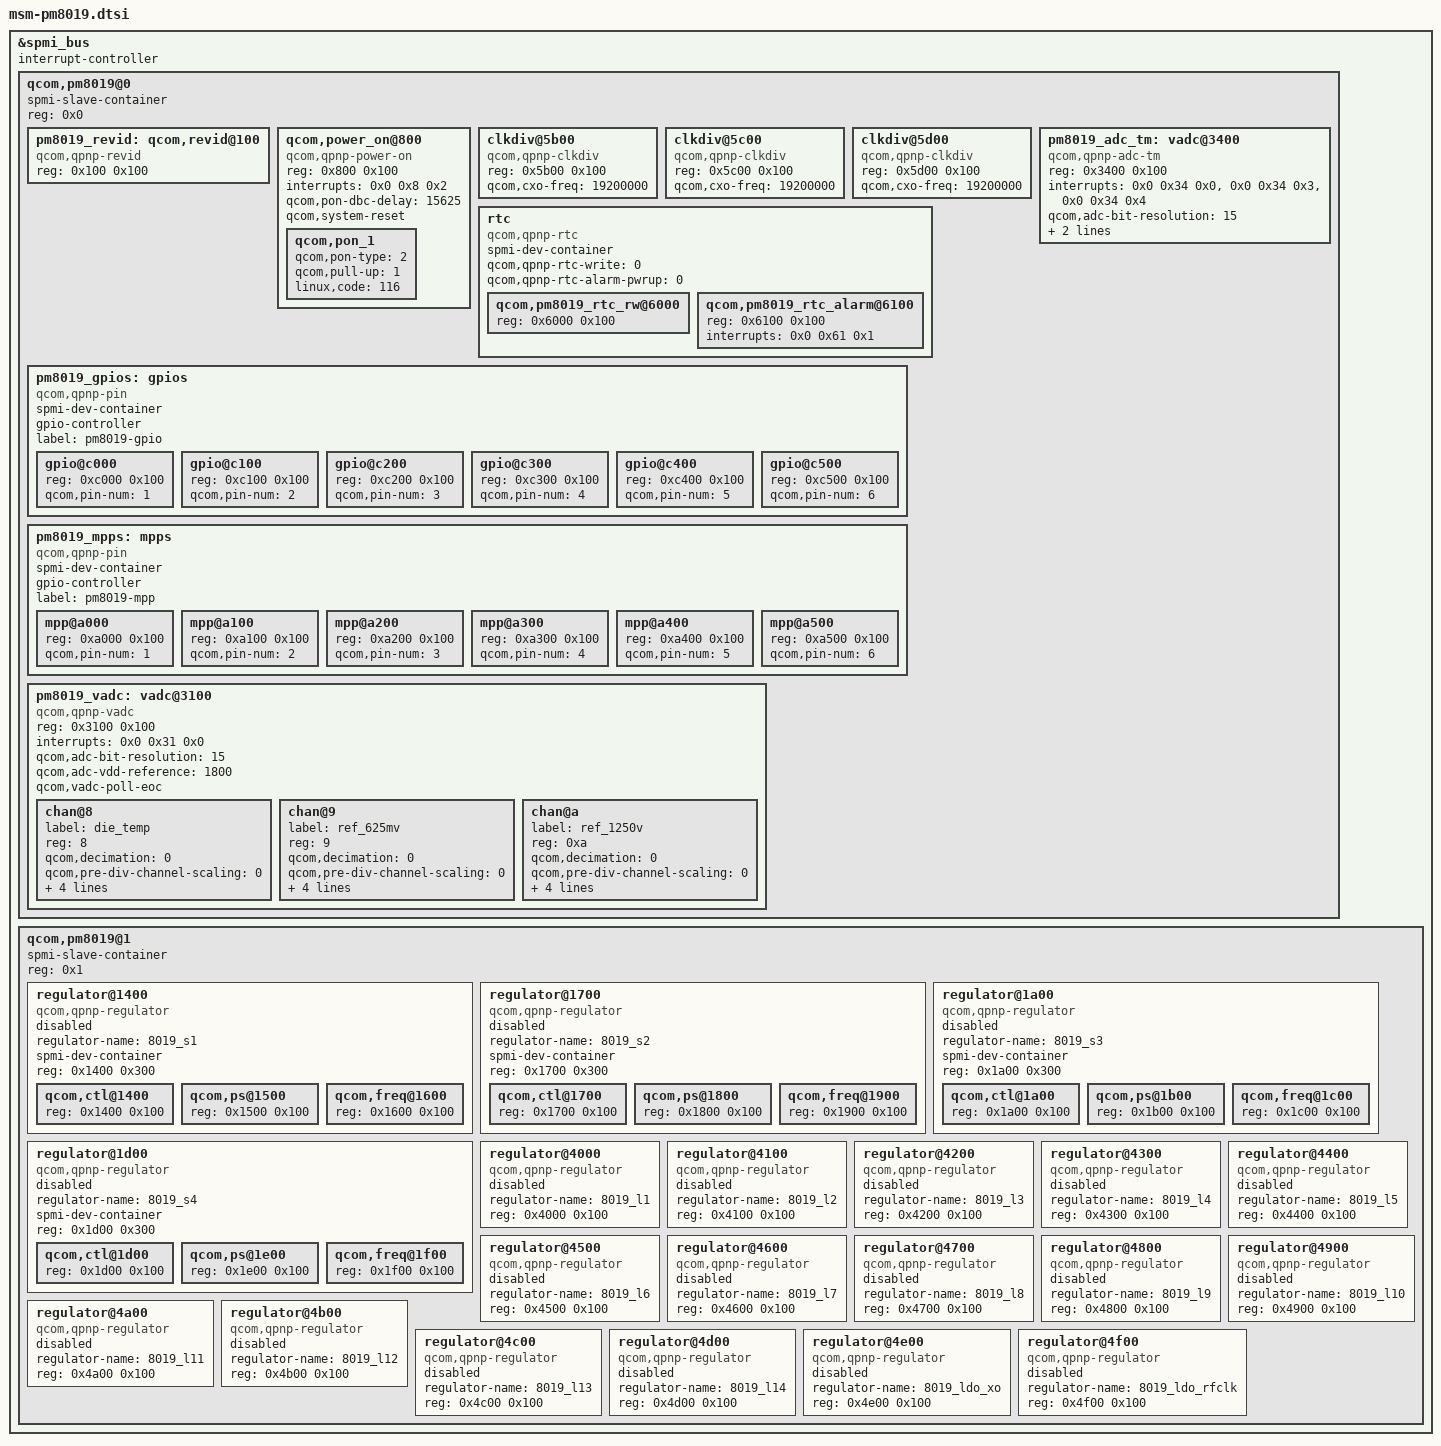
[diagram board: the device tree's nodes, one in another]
/* Copyright (c) 2012,2013,2015, Linux Foundation. All rights reserved.
 *
 * This program is free software; you can redistribute it and/or modify
 * it under the terms of the GNU General Public License version 2 and
 * only version 2 as published by the Free Software Foundation.
 *
 * This program is distributed in the hope that it will be useful,
 * but WITHOUT ANY WARRANTY; without even the implied warranty of
 * MERCHANTABILITY or FITNESS FOR A PARTICULAR PURPOSE.  See the
 * GNU General Public License for more details.
 */

&spmi_bus {
	#address-cells = <1>;
	#size-cells = <0>;
	interrupt-controller;
	#interrupt-cells = <3>;

	qcom,pm8019@0 {
		spmi-slave-container;
		reg = <0x0>;
		#address-cells = <1>;
		#size-cells = <1>;

		pm8019_revid: qcom,revid@100 {
			compatible = "qcom,qpnp-revid";
			reg = <0x100 0x100>;
		};

		qcom,power_on@800 {
			compatible = "qcom,qpnp-power-on";
			reg = <0x800 0x100>;
			interrupts = <0x0 0x8 0x2>;
			interrupt-names = "cblpwr";
			qcom,pon-dbc-delay = <15625>;
			qcom,system-reset;

			qcom,pon_1 {
				qcom,pon-type = <2>;
				qcom,pull-up = <1>;
				linux,code = <116>;
			};
		};

		clkdiv@5b00 {
			reg = <0x5b00 0x100>;
			compatible = "qcom,qpnp-clkdiv";
			qcom,cxo-freq = <19200000>;
		};

		clkdiv@5c00 {
			reg = <0x5c00 0x100>;
			compatible = "qcom,qpnp-clkdiv";
			qcom,cxo-freq = <19200000>;
		};

		clkdiv@5d00 {
			reg = <0x5d00 0x100>;
			compatible = "qcom,qpnp-clkdiv";
			qcom,cxo-freq = <19200000>;
		};

		rtc {
			spmi-dev-container;
			compatible = "qcom,qpnp-rtc";
			#address-cells = <1>;
			#size-cells = <1>;
			qcom,qpnp-rtc-write = <0>;
			qcom,qpnp-rtc-alarm-pwrup = <0>;

			qcom,pm8019_rtc_rw@6000 {
				reg = <0x6000 0x100>;
			};

			qcom,pm8019_rtc_alarm@6100 {
				reg = <0x6100 0x100>;
				interrupts = <0x0 0x61 0x1>;
			};
		};

		pm8019_gpios: gpios {
			spmi-dev-container;
			compatible = "qcom,qpnp-pin";
			gpio-controller;
			#gpio-cells = <2>;
			#address-cells = <1>;
			#size-cells = <1>;
			label = "pm8019-gpio";

			gpio@c000 {
				reg = <0xc000 0x100>;
				qcom,pin-num = <1>;
			};

			gpio@c100 {
				reg = <0xc100 0x100>;
				qcom,pin-num = <2>;
			};

			gpio@c200 {
				reg = <0xc200 0x100>;
				qcom,pin-num = <3>;
			};

			gpio@c300 {
				reg = <0xc300 0x100>;
				qcom,pin-num = <4>;
			};

			gpio@c400 {
				reg = <0xc400 0x100>;
				qcom,pin-num = <5>;
			};

			gpio@c500 {
				reg = <0xc500 0x100>;
				qcom,pin-num = <6>;
			};
		};

		pm8019_mpps: mpps {
			spmi-dev-container;
			compatible = "qcom,qpnp-pin";
			gpio-controller;
			#gpio-cells = <2>;
			#address-cells = <1>;
			#size-cells = <1>;
			label = "pm8019-mpp";

			mpp@a000 {
				reg = <0xa000 0x100>;
				qcom,pin-num = <1>;
			};

			mpp@a100 {
				reg = <0xa100 0x100>;
				qcom,pin-num = <2>;
			};

			mpp@a200 {
				reg = <0xa200 0x100>;
				qcom,pin-num = <3>;
			};

			mpp@a300 {
				reg = <0xa300 0x100>;
				qcom,pin-num = <4>;
			};

			mpp@a400 {
				reg = <0xa400 0x100>;
				qcom,pin-num = <5>;
			};

			mpp@a500 {
				reg = <0xa500 0x100>;
				qcom,pin-num = <6>;
			};
		};

		pm8019_vadc: vadc@3100 {
			compatible = "qcom,qpnp-vadc";
			reg = <0x3100 0x100>;
			#address-cells = <1>;
			#size-cells = <0>;
			interrupts = <0x0 0x31 0x0>;
			interrupt-names = "eoc-int-en-set";
			qcom,adc-bit-resolution = <15>;
			qcom,adc-vdd-reference = <1800>;
			qcom,vadc-poll-eoc;

			chan@8 {
				label = "die_temp";
				reg = <8>;
				qcom,decimation = <0>;
				qcom,pre-div-channel-scaling = <0>;
				qcom,calibration-type = "absolute";
				qcom,scale-function = <3>;
				qcom,hw-settle-time = <0>;
				qcom,fast-avg-setup = <0>;
			};

			chan@9 {
				label = "ref_625mv";
				reg = <9>;
				qcom,decimation = <0>;
				qcom,pre-div-channel-scaling = <0>;
				qcom,calibration-type = "absolute";
				qcom,scale-function = <0>;
				qcom,hw-settle-time = <0>;
				qcom,fast-avg-setup = <0>;
			};

			chan@a {
				label = "ref_1250v";
				reg = <0xa>;
				qcom,decimation = <0>;
				qcom,pre-div-channel-scaling = <0>;
				qcom,calibration-type = "absolute";
				qcom,scale-function = <0>;
				qcom,hw-settle-time = <0>;
				qcom,fast-avg-setup = <0>;
			};
		};

		pm8019_adc_tm: vadc@3400 {
			compatible = "qcom,qpnp-adc-tm";
			reg = <0x3400 0x100>;
			#address-cells = <1>;
			#size-cells = <0>;
			interrupts =	<0x0 0x34 0x0>,
					<0x0 0x34 0x3>,
				     <0x0 0x34 0x4>;
			interrupt-names =	"eoc-int-en-set",
						"high-thr-en-set",
						"low-thr-en-set";
			qcom,adc-bit-resolution = <15>;
			qcom,adc_tm-vadc = <&pm8019_vadc>;
			qcom,adc-vdd-reference = <1800>;
		};
	};

	qcom,pm8019@1 {
		spmi-slave-container;
		reg = <0x1>;
		#address-cells = <1>;
		#size-cells = <1>;

		regulator@1400 {
			regulator-name = "8019_s1";
			spmi-dev-container;
			#address-cells = <1>;
			#size-cells = <1>;
			compatible = "qcom,qpnp-regulator";
			reg = <0x1400 0x300>;
			status = "disabled";

			qcom,ctl@1400 {
				reg = <0x1400 0x100>;
			};
			qcom,ps@1500 {
				reg = <0x1500 0x100>;
			};
			qcom,freq@1600 {
				reg = <0x1600 0x100>;
			};
		};

		regulator@1700 {
			regulator-name = "8019_s2";
			spmi-dev-container;
			#address-cells = <1>;
			#size-cells = <1>;
			compatible = "qcom,qpnp-regulator";
			reg = <0x1700 0x300>;
			status = "disabled";

			qcom,ctl@1700 {
				reg = <0x1700 0x100>;
			};
			qcom,ps@1800 {
				reg = <0x1800 0x100>;
			};
			qcom,freq@1900 {
				reg = <0x1900 0x100>;
			};
		};

		regulator@1a00 {
			regulator-name = "8019_s3";
			spmi-dev-container;
			#address-cells = <1>;
			#size-cells = <1>;
			compatible = "qcom,qpnp-regulator";
			reg = <0x1a00 0x300>;
			status = "disabled";

			qcom,ctl@1a00 {
				reg = <0x1a00 0x100>;
			};
			qcom,ps@1b00 {
				reg = <0x1b00 0x100>;
			};
			qcom,freq@1c00 {
				reg = <0x1c00 0x100>;
			};
		};

		regulator@1d00 {
			regulator-name = "8019_s4";
			spmi-dev-container;
			#address-cells = <1>;
			#size-cells = <1>;
			compatible = "qcom,qpnp-regulator";
			reg = <0x1d00 0x300>;
			status = "disabled";

			qcom,ctl@1d00 {
				reg = <0x1d00 0x100>;
			};
			qcom,ps@1e00 {
				reg = <0x1e00 0x100>;
			};
			qcom,freq@1f00 {
				reg = <0x1f00 0x100>;
			};
		};

		regulator@4000 {
			regulator-name = "8019_l1";
			reg = <0x4000 0x100>;
			compatible = "qcom,qpnp-regulator";
			status = "disabled";
		};

		regulator@4100 {
			regulator-name = "8019_l2";
			reg = <0x4100 0x100>;
			compatible = "qcom,qpnp-regulator";
			status = "disabled";
		};

		regulator@4200 {
			regulator-name = "8019_l3";
			reg = <0x4200 0x100>;
			compatible = "qcom,qpnp-regulator";
			status = "disabled";
		};

		regulator@4300 {
			regulator-name = "8019_l4";
			reg = <0x4300 0x100>;
			compatible = "qcom,qpnp-regulator";
			status = "disabled";
		};

		regulator@4400 {
			regulator-name = "8019_l5";
			reg = <0x4400 0x100>;
			compatible = "qcom,qpnp-regulator";
			status = "disabled";
		};

		regulator@4500 {
			regulator-name = "8019_l6";
			reg = <0x4500 0x100>;
			compatible = "qcom,qpnp-regulator";
			status = "disabled";
		};

		regulator@4600 {
			regulator-name = "8019_l7";
			reg = <0x4600 0x100>;
			compatible = "qcom,qpnp-regulator";
			status = "disabled";
		};

		regulator@4700 {
			regulator-name = "8019_l8";
			reg = <0x4700 0x100>;
			compatible = "qcom,qpnp-regulator";
			status = "disabled";
		};

		regulator@4800 {
			regulator-name = "8019_l9";
			reg = <0x4800 0x100>;
			compatible = "qcom,qpnp-regulator";
			status = "disabled";
		};

		regulator@4900 {
			regulator-name = "8019_l10";
			reg = <0x4900 0x100>;
			compatible = "qcom,qpnp-regulator";
			status = "disabled";
		};

		regulator@4a00 {
			regulator-name = "8019_l11";
			reg = <0x4a00 0x100>;
			compatible = "qcom,qpnp-regulator";
			status = "disabled";
		};

		regulator@4b00 {
			regulator-name = "8019_l12";
			reg = <0x4b00 0x100>;
			compatible = "qcom,qpnp-regulator";
			status = "disabled";
		};

		regulator@4c00 {
			regulator-name = "8019_l13";
			reg = <0x4c00 0x100>;
			compatible = "qcom,qpnp-regulator";
			status = "disabled";
		};

		regulator@4d00 {
			regulator-name = "8019_l14";
			reg = <0x4d00 0x100>;
			compatible = "qcom,qpnp-regulator";
			status = "disabled";
		};

		regulator@4e00 {
			regulator-name = "8019_ldo_xo";
			reg = <0x4e00 0x100>;
			compatible = "qcom,qpnp-regulator";
			status = "disabled";
		};

		regulator@4f00 {
			regulator-name = "8019_ldo_rfclk";
			reg = <0x4f00 0x100>;
			compatible = "qcom,qpnp-regulator";
			status = "disabled";
		};
	};
};
